# M030GAE register map
File version: 1.0
Registers are 32-bit, read-write, reset 0x0 unless marked. A register's access mark holds for its fields unless they carry their own. Offsets are from the block's base; [hi:lo] are bit positions.

## SYS — SYS Register Map
Base 0x40000000
0x00 SYS_PDID ro reset not defined — Part Device Identification Number Register
  [31:0] PDID — Part Device Identification Number (Read Only). This register reflects device part number code. Software can read this register to identify which device is used.
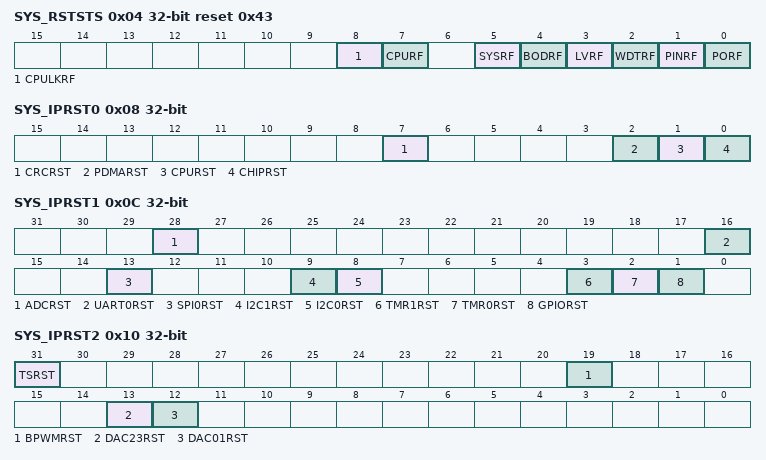
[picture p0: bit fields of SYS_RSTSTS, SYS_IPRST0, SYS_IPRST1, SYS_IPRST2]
0x04 SYS_RSTSTS reset 0x43 — System Reset Status Register
  [8] CPULKRF — CPU Lockup Reset Flag. Note 1: Write 1 to clear this bit to 0. Note 2: When CPU lockup happened under ICE is connected, This flag will set to 1 but chip will not reset.
    0=No reset from CPU lockup happened; 1=The Cortex-M0 lockup happened and chip is reset
  [7] CPURF — CPU Reset Flag. The CPU reset flag is set by hardware if software writes CPURST (SYS_IPRST0[1]) 1 to reset Cortex- M0 Core and Flash Memory Controller (FMC). Note: Write to clear this bit to 0.
    0=No reset from CPU; 1=The Cortex-M0 Core and FMC are reset by software setting CPURST to 1
  [5] SYSRF — System Reset Flag. The system reset flag is set by the 'Reset Signal' from the Cortex-M0 Core to indicate the previous reset source. Note: Write 1 to clear this bit to 0.
    0=No reset from Cortex-M0; 1=The Cortex- M0 had issued the reset signal to reset the system by writing 1 to the bit SYSRESETREQ(AIRCR[2], Application Interrupt and Reset Control Register, address = 0xE000ED0C) in system control registers of Cortex-M0 core
  [4] BODRF — BOD Reset Flag. The BOD reset flag is set by the 'Reset Signal' from the Brown-Out Detector to indicate the previous reset source. Note: Write 1 to clear this bit to 0.
    0=No reset from BOD; 1=The BOD had issued the reset signal to reset the system
  [3] LVRF — LVR Reset Flag. The LVR reset flag is set by the 'Reset Signal' from the Low Voltage Reset Controller to indicate the previous reset source. Note: Write 1 to clear this bit to 0.
    0=No reset from LVR; 1=LVR controller had issued the reset signal to reset the system
  [2] WDTRF — WDT Reset Flag. The WDT reset flag is set by the 'Reset Signal' from the Watchdog Timer or Window Watchdog Timer to indicate the previous reset source. Note 1: Write 1 to clear this bit to 0. Note 2: Watchdog Timer register RSTF(WDT_CTL[2]) bit is set if the system has been reset by WDT time-out reset. Window Watchdog Timer register WWDTRF(WWDT_STATUS[1]) bit is set if the system has been reset by WWDT time-out reset.
    0=No reset from watchdog timer or window watchdog timer; 1=The watchdog timer or window watchdog timer had issued the reset signal to reset the system
  [1] PINRF — NRESET Pin Reset Flag. The nRESET pin reset flag is set by the 'Reset Signal' from the nRESET Pin to indicate the previous reset source. Note: Write 1 to clear this bit to 0.
    0=No reset from nRESET pin; 1=Pin nRESET had issued the reset signal to reset the system
  [0] PORF — POR Reset Flag. The POR reset flag is set by the 'Reset Signal' from the Power-on Reset (POR) Controller or bit CHIPRST (SYS_IPRST0[0]) to indicate the previous reset source. Note: Write 1 to clear this bit to 0.
    0=No reset from POR or CHIPRST; 1=Power-on Reset (POR) or CHIPRST had issued the reset signal to reset the system
0x08 SYS_IPRST0 — Peripheral Reset Control Register 0
  [7] CRCRST — CRC Calculation Controller Reset (Write Protect). Set this bit to 1 will generate a reset signal to the CRC calculation controller. User needs to set this bit to 0 to release from the reset state. Note: This bit is write protected. Refer to the SYS_REGLCTL register.
    0=CRC calculation controller normal operation; 1=CRC calculation controller reset
  [2] PDMARST — PDMA Controller Reset (Write Protect). Setting this bit to 1 will generate a reset signal to the PDMA. User needs to set this bit to 0 to release from reset state. Note: This bit is write protected. Refer to the SYS_REGLCTL register.
    0=PDMA controller normal operation; 1=PDMA controller reset
  [1] CPURST — Processor Core One-shot Reset (Write Protect). Setting this bit will only reset the processor core and Flash Memory Controller(FMC), and this bit will automatically return to 0 after 2 clock cycles. Note: This bit is write protected. Refer to the SYS_REGLCTL register.
    0=Processor core normal operation; 1=Processor core one-shot reset
  [0] CHIPRST — Chip One-shot Reset (Write Protect). Setting this bit will reset the whole chip, including processor core and all peripherals, and this bit will automatically return to 0 after the 2 clock cycles. The CHIPRST is same as the POR reset, all the chip controllers is reset and the chip setting from Flash are also reload. About the difference between CHIPRST and SYSRESETREQ(AIRCR[2]), please refer to section 6.2.2. Note 1: This bit is write protected. Refer to the SYS_REGLCTL register. Note 2: Reset by power on reset.
    0=Chip normal operation; 1=Chip one-shot reset
0x0C SYS_IPRST1 — Peripheral Reset Control Register 1
  [28] ADCRST — ADC Controller Reset
    0=ADC controller normal operation; 1=ADC controller reset
  [16] UART0RST — UART0 Controller Reset
    0=UART0 controller normal operation; 1=UART0 controller reset
  [13] SPI0RST — SPI0 Controller Reset
    0=SPI0 controller normal operation; 1=SPI0 controller reset
  [9] I2C1RST — I2C1 Controller Reset
    0=I2C1 controller normal operation; 1=I2C1 controller reset
  [8] I2C0RST — I2C0 Controller Reset
    0=I2C0 controller normal operation; 1=I2C0 controller reset
  [3] TMR1RST — Timer1 Controller Reset
    0=Timer1 controller normal operation; 1=Timer1 controller reset
  [2] TMR0RST — Timer0 Controller Reset
    0=Timer0 controller normal operation; 1=Timer0 controller reset
  [1] GPIORST — GPIO Controller Reset
    0=GPIO controller normal operation; 1=GPIO controller reset
0x10 SYS_IPRST2 — Peripheral Reset Control Register 2
  [31] TSRST — Temperature Sensor Reset
    0=Temperature Sensor normal operation; 1=Temperature Sensor reset
  [19] BPWMRST — BPWM Controller Reset
    0=BPWM controller normal operation; 1=BPWM controller reset
  [13] DAC23RST — DAC23 Controller Reset
    0=DAC2 and DAC3 controller normal operation; 1=DAC2 and DAC3 controller reset
  [12] DAC01RST — DAC01 Controller Reset
    0=DAC0 and DAC1 controller normal operation; 1=DAC0 and DAC1 controller reset
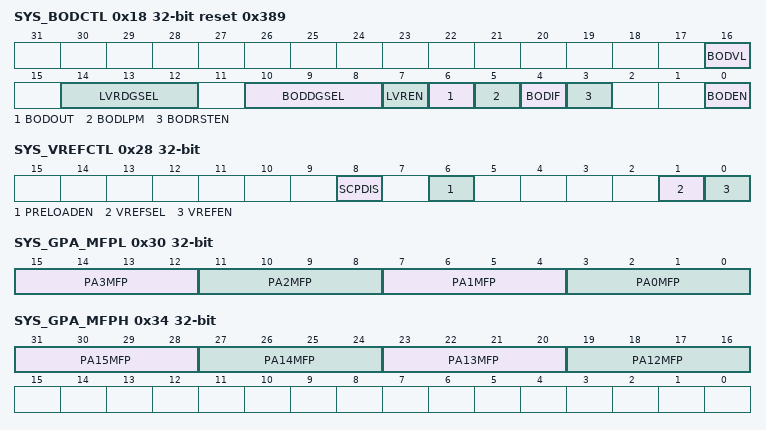
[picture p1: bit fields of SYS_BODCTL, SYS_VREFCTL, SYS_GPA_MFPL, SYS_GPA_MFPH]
0x18 SYS_BODCTL reset 0x389 — Brown-out Detector Control Register
  [16] BODVL — Brown-out Detector Threshold Voltage Select (Write Protect). Note 1: This bit is write protected. Refer to the SYS_REGLCTL register. Note 2: Reset by power on reset.
    0=Brown-Out Detector threshold voltage is 2.5V; 1=Brown-Out Detector threshold voltage is 2.7V
  [14:12] LVRDGSEL — LVR Output De-glitch Time Select (Write Protect). Note: These bits are write protected. Refer to the SYS_REGLCTL register.
    0=Without de-glitch function; 1=64 system clock (HCLK); 2=128 system clock (HCLK); 3=256 system clock (HCLK); 4=512 system clock (HCLK); 5=1024 system clock (HCLK); 6=2048 system clock (HCLK); 7=4096 system clock (HCLK)
  [10:8] BODDGSEL — Brown-out Detector Output De-glitch Time Select (Write Protect). Note: These bits are write protected. Refer to the SYS_REGLCTL register.
    0=BOD output is sampled by LIRC/4 clock; 1=64 system clock (HCLK); 2=128 system clock (HCLK); 3=256 system clock (HCLK); 4=512 system clock (HCLK); 5=1024 system clock (HCLK); 6=2048 system clock (HCLK); 7=4096 system clock (HCLK)
  [7] LVREN — Low Voltage Reset Enable Bit (Write Protect). The LVR function resets the chip when the input power voltage is lower than LVR circuit setting. LVR function is enabled by default. Note 1: After enabling the bit, the LVR function will be active with 200us delay for LVR output stable (Default). Note 2: This bit is write protected. Refer to the SYS_REGLCTL register.
    0=Low Voltage Reset function Disabled; 1=Low Voltage Reset function Enabled
  [6] BODOUT — Brown-out Detector Output Status. It means the detected voltage is lower than BODVL setting. If the BODEN is 0, BOD function disabled , this bit always responds 0000.
    0=Brown-out Detector output status is 0; 1=Brown-out Detector output status is 1
  [5] BODLPM — Brown-out Detector Low Power Mode (Write Protect). Note 1: The BOD consumes about 2uA in normal mode, the BOD low power mode can reduce the current to about 1/30 but slow the BOD response. Note 2: This bit is write protected. Refer to the SYS_REGLCTL register.
    0=BOD operate in normal mode (Default); 1=BOD low power mode Enabled
  [4] BODIF — Brown-out Detector Interrupt Flag. Note: Write 1 to clear this bit to 0.
    0=Brown-out Detector does not detect any voltage draft at VDD down through or up through the voltage of BODVL setting; 1=When Brown-out Detector detects the VDD is dropped down through the voltage of BODVL setting or the VDD is raised up through the voltage of BODVL setting, this bit is set to 1 and the brown-out interrupt is requested if brown-out interrupt is enabled
  [3] BODRSTEN — Brown-out Reset Enable Bit (Write Protect). Note 1: While the Brown-out Detector function is enabled (BODEN high) and BOD reset function is enabled (BODRSTEN high), BOD will assert a signal to reset chip when the detected voltage is lower than the threshold (BODOUT high). While the BOD function is enabled (BODEN high) and BOD interrupt function is enabled (BODRSTEN low), BOD will assert an interrupt if BODOUT is high. BOD interrupt will keep untill the BODEN set to 0. BOD interrupt can be blocked by disabling the NVIC BOD interrupt or disabling BOD function (set BODEN low). Note 2: This bit is write protected. Refer to the SYS_REGLCTL register. Note 3: Reset by power on reset
    0=Brown-out 'INTERRUPT' function Enabled; 1=Brown-out 'RESET' function Enabled
  [0] BODEN — Brown-out Detector Enable Bit (Write Protect). Note 1: This bit is write protected. Refer to the SYS_REGLCTL register. Note 2: Reset by power on reset
    0=Brown-out Detector function Disabled; 1=Brown-out Detector function Enabled
0x24 SYS_PORCTL — Power-On-reset Controller Register
  [15:0] POROFF — Power-on Reset Enable Bit (Write Protect). When powered on, the POR circuit generates a reset signal to reset the whole chip function, but noise on the power may cause the POR active again. User can disable internal POR circuit to avoid unpredictable noise to cause chip reset by writing 0x5AA5 to this field. The POR function will be active again when this field is set to another value or chip is reset by other reset source, including: nRESET, Watchdog, LVR reset, BOD reset, ICE reset command and the software-chip reset function. Note: This bit is write protected. Refer to the SYS_REGLCTL register.
0x28 SYS_VREFCTL — Voltage Reference Control Register
  [8] SCPDIS — VREF Short Circuit Protection Disable Control (Write Protect)
    0=VREF Short Circuit Protection function Enabled. (Default); 1=VREF Short Circuit Protection function Disabled
  [6] PRELOADEN — VREF Pre-load Enable Bit (Write Protect). This bit is set automatically if software set VREFEN (SYS_VREFCTL[0]) to 1.
    0=VREF Pre-load function Disabled. (Default); 1=VREF Pre-load function Enabled
  [1] VREFSEL — VREF Output Voltage Select (Write Protect). Note: This bit is write protected. Refer to the SYS_REGLCTL register.
    0=VREF output voltage value is 2.048V. (Default); 1=VREF output voltage value is 2.5V
  [0] VREFEN — VREF Enable Bit (Write Protect). Note: This bit is write protected. Refer to the SYS_REGLCTL register.
    0=VREF function Disabled. (Default); 1=VREF function Enabled
0x30 SYS_GPA_MFPL — GPIOA Low Byte Multiple Function Control Register
  [15:12] PA3MFP — PA.3 Multi-function Pin Selection
  [11:8] PA2MFP — PA.2 Multi-function Pin Selection
  [7:4] PA1MFP — PA.1 Multi-function Pin Selection
  [3:0] PA0MFP — PA.0 Multi-function Pin Selection
0x34 SYS_GPA_MFPH — GPIOA High Byte Multiple Function Control Register
  [31:28] PA15MFP — PA.15 Multi-function Pin Selection
  [27:24] PA14MFP — PA.14 Multi-function Pin Selection
  [23:20] PA13MFP — PA.13 Multi-function Pin Selection
  [19:16] PA12MFP — PA.12 Multi-function Pin Selection
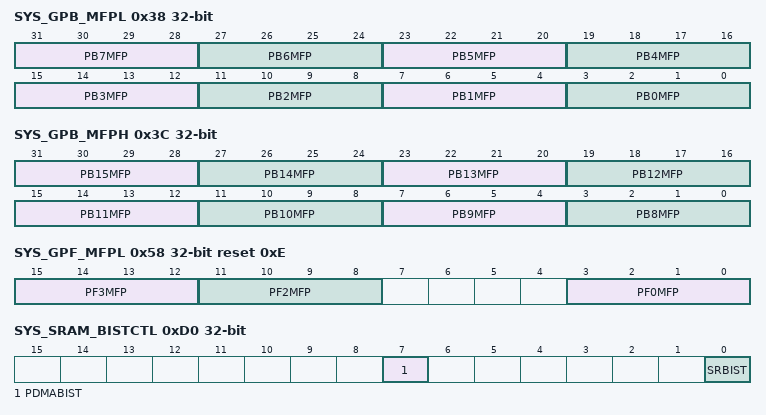
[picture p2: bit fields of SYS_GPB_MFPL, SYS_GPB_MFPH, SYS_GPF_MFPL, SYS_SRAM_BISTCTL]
0x38 SYS_GPB_MFPL — GPIOB Low Byte Multiple Function Control Register
  [31:28] PB7MFP — PB.7 Multi-function Pin Selection
  [27:24] PB6MFP — PB.6 Multi-function Pin Selection
  [23:20] PB5MFP — PB.5 Multi-function Pin Selection
  [19:16] PB4MFP — PB.4 Multi-function Pin Selection
  [15:12] PB3MFP — PB.3 Multi-function Pin Selection
  [11:8] PB2MFP — PB.2 Multi-function Pin Selection
  [7:4] PB1MFP — PB.1 Multi-function Pin Selection
  [3:0] PB0MFP — PB.0 Multi-function Pin Selection
0x3C SYS_GPB_MFPH — GPIOB High Byte Multiple Function Control Register
  [31:28] PB15MFP — PB.15 Multi-function Pin Selection
  [27:24] PB14MFP — PB.14 Multi-function Pin Selection
  [23:20] PB13MFP — PB.13 Multi-function Pin Selection
  [19:16] PB12MFP — PB.12 Multi-function Pin Selection
  [15:12] PB11MFP — PB.11 Multi-function Pin Selection
  [11:8] PB10MFP — PB.10 Multi-function Pin Selection
  [7:4] PB9MFP — PB.9 Multi-function Pin Selection
  [3:0] PB8MFP — PB.8 Multi-function Pin Selection
0x40 SYS_GPC_MFPL — GPIOC Low Byte Multiple Function Control Register
  [7:4] PC1MFP — PC.1 Multi-function Pin Selection
0x58 SYS_GPF_MFPL reset 0xE — GPIOF Low Byte Multiple Function Control Register
  [15:12] PF3MFP — PF.3 Multi-function Pin Selection
  [11:8] PF2MFP — PF.2 Multi-function Pin Selection
  [3:0] PF0MFP — PF.0 Multi-function Pin Selection
0xD0 SYS_SRAM_BISTCTL — System SRAM BIST Test Control Register
  [7] PDMABIST — PDMA SRAM BIST Enable Bit (Write Protect). This bit enables BIST test for PDMA SRAM. Note: This bit is write protected. Refer to the SYS_REGLCTL register.
    0=PDMA SRAM BIST Disabled; 1=PDMA SRAM BIST Enabled
  [0] SRBIST — System SRAM BIST Enable Bit (Write Protect). This bit enables BIST test for System SRAM. Note: This bit is write protected. Refer to the SYS_REGLCTL register.
    0=System SRAM BIST Disabled; 1=System SRAM BIST Enabled
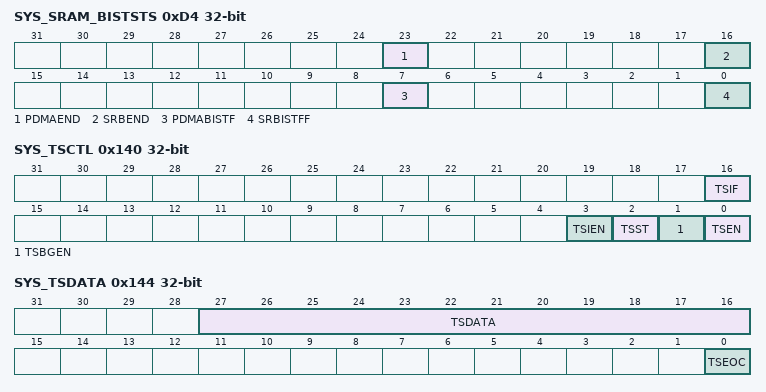
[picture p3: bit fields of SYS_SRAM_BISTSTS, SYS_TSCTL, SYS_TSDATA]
0xD4 SYS_SRAM_BISTSTS ro (reset mask 0xFF00FF00) — System SRAM BIST Test Status Register
  [23] PDMAEND — PDMA SRAM BIST Test Finish
    0=PDMA SRAM BIST is active; 1=PDMA SRAM BIST test finish
  [16] SRBEND — System SRAM BIST Test Finish
    0=System SRAM BIST active; 1=System SRAM BIST finish
  [7] PDMABISTF — PDMA SRAM BIST Failed Flag
    0=PDMA SRAM BIST pass; 1=PDMA SRAM BIST failed
  [0] SRBISTFF — System SRAM BIST Fail Flag
    0=System SRAM BIST test pass; 1=System SRAM BIST test fail
0x100 SYS_REGLCTL — Register Lock Control Register
  [7:0] REGLCTL — Register Lock Control Code. Some registers have write-protection function. Writing these registers have to disable the protected function by writing the sequence value '59h', '16h', '88h' to this field. After this sequence is completed, the REGLCTL bit will be set to 1 and write-protection registers can be normal write. REGLCTL[0]. Register Lock Control Disable Index
    0=Write-protection Enabled for writing protected registers. Any write to the protected register is ignored; 1=Write-protection Disabled for writing protected registers
0x140 SYS_TSCTL — Temperature Sensor Control Register
  [16] TSIF — Temperature Sensor Interrupt Flag. This bit indicates the end of temperature sensor conversion. This bit will be set automatically when temperature sensor conversion is finished. Note: Write 1 to clear this to 0.
    0=Tempertaure Sensor conversion not finished; 1=Tempertaure Sensor conversion finished
  [3] TSIEN — Temperature Sensor Interrupt Enable Bit. If this bit is set to 1, temperature sensor interrupt is requested when TSIF (SYS_TSCTL[16]) is set.
    0=Temperature Sensor finish interrupt Disabled. (Default); 1=Temperature Sensor finish interrupt Enabled
  [2] TSST — Temperature Sensor Conversion Start. Note 1: User needs to set TSEN first, and wait for at least 200us to start temperature sensor conversion. Note 2: This bit will be cleared to 0 by hardware automatically when temperature sensor conversion is finished.
    0=Conversion stoped or finished. (Default); 1=Conversion starts
  [1] TSBGEN — Temperature Sensor Bandgap Enable Bit. If this bit is set to 1, Temperature sensor bandgap will be enabled and Temperature sensor will supply current source to DAC and Internal Voltage Reference. Note: After TSBGEN is set, users should wait 200us stable time to enable DACEN(DACx_CTL[0]) or VREFEN (SYS_VREFCTL[0]).
    0=Temperature Sensor Bandgap function Disabled. (Default); 1=Temperature Sensor Bandgap function Enabled
  [0] TSEN — Temperature Sensor Enable Bit
    0=Temperature Sensor function Disabled. (Default); 1=Temperature Sensor function Enabled
0x144 SYS_TSDATA — Temperature Sensor Data Register
  [27:16] TSDATA ro — Temperature Sensor Conversion Data Bits (Read Only). This field present the conversion result of Temperature Sensor, ranges from -40C to 105C. Note: Negative temperature is represented by 2's complement format, and per LSB difference is equivalent to 0.0625C
  [0] TSEOC — Temperature Sensor Conversion Finish Flag. This bit indicates the end of temperature sensor conversion. Note: Write 1 to clear this bit to 0.
0x1E8 SYS_POR18DISAN — Analog POR18 Disable Control Register
  [15:0] POR18OFFAN — LDO Power-on Reset Enable Bit (Write Protect). After powered on, user can turn off internal analog POR18 circuit to save power by writing 0x5AA5 to this field. The analog POR18 circuit will be active again when this field is set to another value or chip is reset by other reset source, including: nRESET, Watchdog, LVR reset, BOD reset, ICE reset command and the software-chip reset function. Note: This bit is write protected. Refer to the SYS_REGLCTL register.
